# LKS32MC07x register map
Vendor: Linko Ltd.; Series: LKS32MC07x; File version: 1.0
CPU: CM0 r1p0, little endian, MPU, no FPU, 3 interrupt priority bits
Registers are 32-bit, read-write, reset 0x0 unless marked. A register's access mark holds for its fields unless they carry their own. Offsets are from the block's base; [hi:lo] are bit positions; {n}, {i} and the like mark numbered series; 'fields as' and 'values as' point back to an identical list.

## ADC0 — ADC0 registers
Base 0x40010400
0x00 DAT0 — 0th sample data
  [15:0] DAT0
0x04 DAT1 — 1st sample data
  [15:0] DAT1
0x08 DAT2 — 2nd sample data
  [15:0] DAT2
0x0C DAT3 — 3rd sample data
  [15:0] DAT3
{0x0+4i} DAT{i} (i=4..13) — {i}th sample data
  [15:0] DAT{i}
0x38 IDAT0 — 0th idle sample data
  [15:0] IDAT0
0x3C IDAT1 — 1th idle sample data
  [15:0] IDAT1
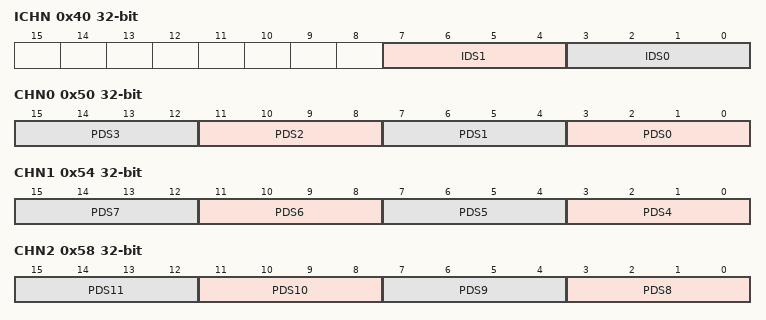
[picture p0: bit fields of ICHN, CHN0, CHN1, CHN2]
0x40 ICHN — idle channel number
  [7:4] IDS1 — Data1 source
    {v}=OPA{v}_OUT (v=0..3); {v}=ADC01_CH{v} (v=4..9); {v}=ADC0_CH{v} (v=10..13); 14=DAC0_OUT; 15=DAC1_OUT
  [3:0] IDS0 — Data0 source
    values as IDS1
0x50 CHN0 — Data0/1/2/3 sample signal source
  [all] fields
    values as ICHN.IDS1
  [4n+3:4n] PDS{n} (n=0..3) — Data{n} source
0x54 CHN1 — Data4/5/6/7 sample signal source
  [all] fields
    values as ICHN.IDS1
  [4n-13:4n-16] PDS{n} (n=4..7) — Data{n} source
0x58 CHN2 — Data8/9/10/11 sample signal source
  [all] fields
    values as ICHN.IDS1
  [4n-29:4n-32] PDS{n} (n=8..11) — Data{n} source
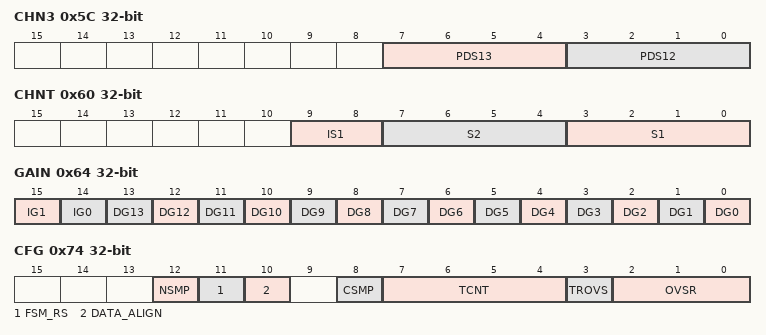
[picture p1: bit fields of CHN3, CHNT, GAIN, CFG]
0x5C CHN3 — Data12/13 sample signal source
  [7:4] PDS13 — Data13 source
    values as ICHN.IDS1
  [3:0] PDS12 — Data12 source
    values as ICHN.IDS1
0x60 CHNT — Round 0/1 channel numbers
  [9:8] IS1 — Idle sample times
  [7:4] S2 — second round sample times
  [3:0] S1 — first round sample times
0x64 GAIN — 0~13th sample gain selection
  [15] IG1 — IDAT1 gain selection
  [14] IG0 — IDAT0 gain selection
  [n] DG{n} (n=0..13) — Data{n} gain selection
0x74 CFG — Configuration
  [12] NSMP — number of sample
    0=ONE_SEG; 1=TWO_SEG
  [11] FSM_RS — sample state machine reset, write to reset ADC FSM; read as ADC_BUSY
  [10] DATA_ALIGN — ADC data alignment
    0=LEFT (left alignment, padding with 4'b0); 1=RIGHT (right alignment, sign bit extension at head)
  [8] CSMP — Continues Sample Mode
  [7:4] TCNT — Evnet Count for one Trig
  [3] TROVS — Over Sample Trig Mode
  [2:0] OVSR — Over Sample Rate
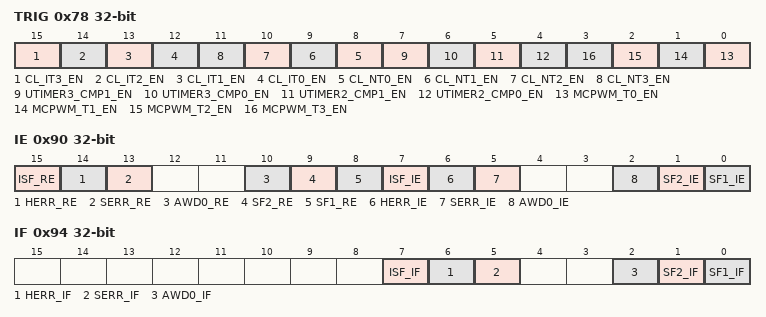
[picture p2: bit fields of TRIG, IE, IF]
0x78 TRIG — Sample trigger config
  [15] CL_IT3_EN — UTIMER3 CMP1 event trigger enable
  [14] CL_IT2_EN — UTIMER3 CMP0 event trigger enable
  [13] CL_IT1_EN — UTIMER2 CMP1 event trigger enable
  [12] CL_IT0_EN — UTIMER2 CMP0 event trigger enable
  [n+8] CL_NT{n}_EN (n=0..3) — MCPWM trigger{n} enable
  [7] UTIMER3_CMP1_EN — UTIMER3 CMP1 event trigger enable
  [6] UTIMER3_CMP0_EN — UTIMER3 CMP0 event trigger enable
  [5] UTIMER2_CMP1_EN — UTIMER2 CMP1 event trigger enable
  [4] UTIMER2_CMP0_EN — UTIMER2 CMP0 event trigger enable
  [n] MCPWM_T{n}_EN (n=0..3) — MCPWM trigger{n} enable
0x7C SWT wo — Software trigger
  [15:0] SWT — write 0x5AA5 to trigger ADC sample
0x80 DC0 — DC offset of S/H A at low gain
  [7:0] DC_OFFSET — DC offset value
0x84 AMC0 — Amplification calibration of S/H A at low gain
  [9:0] AMC — Amplification calibration value
0x88 DC1 — DC offset of S/H A at high gain
  [7:0] DC_OFFSET — DC offset value
0x8C AMC1 — Amplification calibration of S/H A at high gain
  [9:0] AM_CALI — Amplification calibration value
0x90 IE — Interrupt enable
  [15] ISF_RE — Threshold reached DMA request enable
  [14] HERR_RE — Hardware trigger error DMA request enable
  [13] SERR_RE — Software trigger error DMA request enable
  [10] AWD0_RE — Threshold reached DMA enable
  [9] SF2_RE — 2nd segment sample finish DMA enable
  [8] SF1_RE — 1st segment sample finish DMA enable
  [7] ISF_IE — Idle sample finish interrupt enable
  [6] HERR_IE — Hardware trigger error interrupt enable
  [5] SERR_IE — Software trigger error interrupt enable
  [2] AWD0_IE — Threshold reached interrupt enable
  [1] SF2_IE — 2nd segment sample finish interrupt enable
  [0] SF1_IE — 1st segment sample finish interrupt enable
0x94 IF — Interrupt flag
  [7] ISF_IF — Idle sample finish interrupt, write 1 to clear
  [6] HERR_IF — Hardware trigger error interrupt, write 1 to clear
  [5] SERR_IF — Software trigger error interrupt, write 1 to clear
  [2] AWD0_IF — Threshold reached interrupt, write 1 to clear
  [1] SF2_IF — 2nd segment sample finish interrupt, write 1 to clear
  [0] SF1_IF — 1st segment sample finish interrupt, write 1 to clear
0xC4 LTH reset 0xF800 (reset mask 0x7FF) — Data low threshold
  [11:0] LTH — ADC data low threshold
0xC8 HTH reset 0x7FF (reset mask 0x7FF) — Data high threshold
  [11:0] HTH — ADC data high threshold
0xCC GEN — Data threshold guarding enable
  [15:0] GEN — ADC threshold guarding enable

## ADC1 — ADC1 registers
Base 0x40010500
Registers as ADC0; these are added or differ:
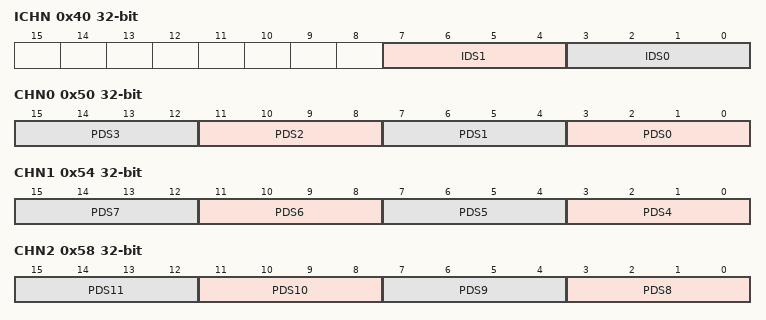
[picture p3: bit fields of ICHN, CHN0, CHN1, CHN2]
0x40 ICHN — idle channel number
  [7:4] IDS1 — Data1 source
    {v}=OPA{v}_OUT (v=0..3); {v}=ADC01_CH{v} (v=4..9); {v}=ADC1_CH{v} (v=10..13); 14=Temp; 15=VSS
  [3:0] IDS0 — Data0 source
    values as IDS1
0x50 CHN0 — Data0/1/2/3 sample signal source
  [all] fields
    values as ICHN.IDS1
  [4n+3:4n] PDS{n} (n=0..3) — Data{n} source
0x54 CHN1 — Data4/5/6/7 sample signal source
  [all] fields
    values as ICHN.IDS1
  [4n-13:4n-16] PDS{n} (n=4..7) — Data{n} source
0x58 CHN2 — Data8/9/10/11 sample signal source
  [all] fields
    values as ICHN.IDS1
  [4n-29:4n-32] PDS{n} (n=8..11) — Data{n} source
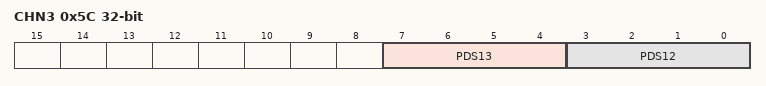
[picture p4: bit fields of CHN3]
0x5C CHN3 — Data12/13 sample signal source
  [7:4] PDS13 — Data13 source
    values as ICHN.IDS1
  [3:0] PDS12 — Data12 source
    values as ICHN.IDS1
